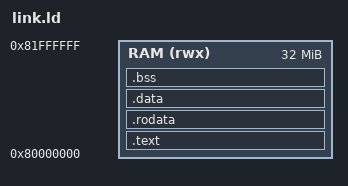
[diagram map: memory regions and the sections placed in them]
ENTRY(_start)
MEMORY { RAM (rwx) : ORIGIN = 0x80000000, LENGTH = 32M }
SECTIONS {
  .text : { KEEP(*(.text.init)) *(.text .text.*) } > RAM
  .rodata : { *(.rodata .rodata.*) *(.srodata .srodata.*) } > RAM
  .data : { *(.data .data.*) *(.sdata .sdata.*) } > RAM
  .bss : { __bss_start = .; *(.bss .bss.*) *(.sbss .sbss.*) *(COMMON) __bss_end = .; } > RAM
  . = ALIGN(16);
  . = . + 256K;
  __stack_top = .;
}
